AUTOSAR XML (schema 4-2-2)
package /STELLANTIS/EPT/SASWCs
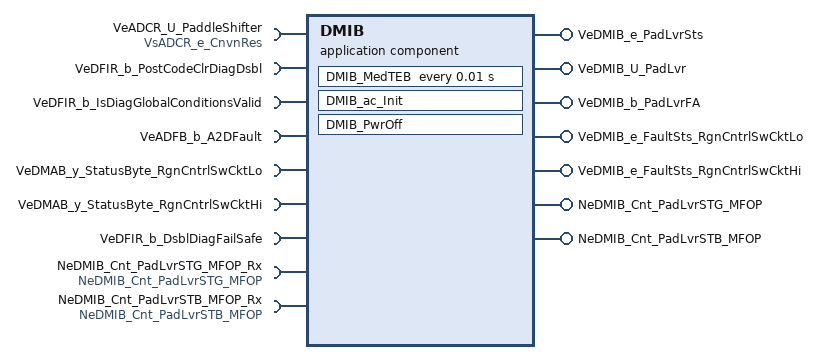
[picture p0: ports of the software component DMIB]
  application sw component type DMIB
    7 x require port:
      VeADCR_U_PaddleShifter: variation-point={short-label=vpVeADCR_U_PaddleShifter, sw-syscond=1}, nonqueued-receiver-com-spec{data-element=VsADCR_e_CnvnRes, init-value={short-label=DefaultInitValue_IDTRAdcInpResData, fields=[0, 0]}}, required-interface=VsADCR_e_CnvnRes
      VeDFIR_b_PostCodeClrDiagDsbl: variation-point={short-label=vpVeDFIR_b_PostCodeClrDiagDsbl, sw-syscond=1}, nonqueued-receiver-com-spec{data-element=Value, init-value=0}, required-interface=VeDFIR_b_PostCodeClrDiagDsbl
      VeDFIR_b_IsDiagGlobalConditionsValid: variation-point={short-label=vpVeDFIR_b_IsDiagGlobalConditionsValid, sw-syscond=1}, nonqueued-receiver-com-spec{data-element=Value, init-value=0}, required-interface=VeDFIR_b_IsDiagGlobalConditionsValid
      VeADFB_b_A2DFault: variation-point={short-label=vpVeADFB_b_A2DFault, sw-syscond=1}, nonqueued-receiver-com-spec{data-element=Value, init-value=0}, required-interface=VeADFB_b_A2DFault
      VeDMAB_y_StatusByte_RgnCntrlSwCktLo: variation-point={short-label=vpVeDMAB_y_StatusByte_RgnCntrlSwCktLo, sw-syscond=1}, nonqueued-receiver-com-spec{data-element=Value, init-value=0}, required-interface=VeDMAB_y_StatusByte_RgnCntrlSwCktLo
      VeDMAB_y_StatusByte_RgnCntrlSwCktHi: variation-point={short-label=vpVeDMAB_y_StatusByte_RgnCntrlSwCktHi, sw-syscond=1}, nonqueued-receiver-com-spec{data-element=Value, init-value=0}, required-interface=VeDMAB_y_StatusByte_RgnCntrlSwCktHi
      VeDFIR_b_DsblDiagFailSafe: variation-point={short-label=vpVeDFIR_b_DsblDiagFailSafe, sw-syscond=1}, nonqueued-receiver-com-spec{data-element=Value, init-value=0}, required-interface=VeDFIR_b_DsblDiagFailSafe
    5 x provide port:
      VeDMIB_e_PadLvrSts: variation-point={short-label=vpVeDMIB_e_PadLvrSts, sw-syscond=1}, nonqueued-sender-com-spec{data-element=Value, init-value=CeDMIR_e_Init}, provided-interface=VeDMIB_e_PadLvrSts
      VeDMIB_U_PadLvr: variation-point={short-label=vpVeDMIB_U_PadLvr, sw-syscond=1}, nonqueued-sender-com-spec{data-element=Value, init-value=0}, provided-interface=VeDMIB_U_PadLvr
      VeDMIB_b_PadLvrFA: variation-point={short-label=vpVeDMIB_b_PadLvrFA, sw-syscond=1}, nonqueued-sender-com-spec{data-element=Value, init-value=0}, provided-interface=VeDMIB_b_PadLvrFA
      VeDMIB_e_FaultSts_RgnCntrlSwCktLo: variation-point={short-label=vpVeDMIB_e_FaultSts_RgnCntrlSwCktLo, sw-syscond=1}, nonqueued-sender-com-spec{data-element=Value, init-value=CeDFIB_e_Init}, provided-interface=VeDMIB_e_FaultSts_RgnCntrlSwCktLo
      VeDMIB_e_FaultSts_RgnCntrlSwCktHi: variation-point={short-label=vpVeDMIB_e_FaultSts_RgnCntrlSwCktHi, sw-syscond=1}, nonqueued-sender-com-spec{data-element=Value, init-value=CeDFIB_e_Init}, provided-interface=VeDMIB_e_FaultSts_RgnCntrlSwCktHi
    require port NeDMIB_Cnt_PadLvrSTG_MFOP_Rx: variation-point={short-label=vpNeDMIB_Cnt_PadLvrSTG_MFOP_Rx, sw-syscond=1}, nv-require-com-spec{init-value=0, variable=NeDMIB_Cnt_PadLvrSTG_MFOP}, required-interface=NeDMIB_Cnt_PadLvrSTG_MFOP
    require port NeDMIB_Cnt_PadLvrSTB_MFOP_Rx: variation-point={short-label=vpNeDMIB_Cnt_PadLvrSTB_MFOP_Rx, sw-syscond=1}, nv-require-com-spec{init-value=0, variable=NeDMIB_Cnt_PadLvrSTB_MFOP}, required-interface=NeDMIB_Cnt_PadLvrSTB_MFOP
    provide port NeDMIB_Cnt_PadLvrSTG_MFOP: nv-provide-com-spec{ram-block-init-value=0, variable=NeDMIB_Cnt_PadLvrSTG_MFOP}, provided-interface=NeDMIB_Cnt_PadLvrSTG_MFOP
    provide port NeDMIB_Cnt_PadLvrSTB_MFOP: nv-provide-com-spec{ram-block-init-value=0, variable=NeDMIB_Cnt_PadLvrSTB_MFOP}, provided-interface=NeDMIB_Cnt_PadLvrSTB_MFOP
    behavior IB_DMIB: data-type-mapping=[msADTtoIDTMapping, ADTtoIDTMapping], handle-termination-and-restart=NO-SUPPORT
      timing event Event_MedTEB: start-on-event=DMIB_MedTEB, period=0.01
      init event Event_DMIB_ac_Init: start-on-event=DMIB_ac_Init
      init event Event_PwrOff: start-on-event=DMIB_PwrOff
      runnable DMIB_ac_Init
        data-receive-point-by-arguments:
          access IN_NeDMIB_Cnt_PadLvrSTB_MFOP_Rx_NeDMIB_Cnt_PadLvrSTB_MFOP: accessed-variable=NeDMIB_Cnt_PadLvrSTB_MFOP_Rx.NeDMIB_Cnt_PadLvrSTB_MFOP, variation-point={short-label=vpIN_NeDMIB_Cnt_PadLvrSTB_MFOP_Rx_NeDMIB_Cnt_PadLvrSTB_MFOP, sw-syscond=1}
          access IN_NeDMIB_Cnt_PadLvrSTG_MFOP_Rx_NeDMIB_Cnt_PadLvrSTG_MFOP: accessed-variable=NeDMIB_Cnt_PadLvrSTG_MFOP_Rx.NeDMIB_Cnt_PadLvrSTG_MFOP, variation-point={short-label=vpIN_NeDMIB_Cnt_PadLvrSTG_MFOP_Rx_NeDMIB_Cnt_PadLvrSTG_MFOP, sw-syscond=1}
        data-send-points:
          4 x access:
            OUT_VeDMIB_e_PadLvrSts_Value: accessed-variable=VeDMIB_e_PadLvrSts.Value, variation-point={short-label=vpOUT_VeDMIB_e_PadLvrSts_Value, sw-syscond=1}
            OUT_VeDMIB_U_PadLvr_Value: accessed-variable=VeDMIB_U_PadLvr.Value, variation-point={short-label=vpOUT_VeDMIB_U_PadLvr_Value, sw-syscond=1}
            OUT_VeDMIB_e_FaultSts_RgnCntrlSwCktLo_Value: accessed-variable=VeDMIB_e_FaultSts_RgnCntrlSwCktLo.Value, variation-point={short-label=vpOUT_VeDMIB_e_FaultSts_RgnCntrlSwCktLo_Value, sw-syscond=1}
            OUT_VeDMIB_e_FaultSts_RgnCntrlSwCktHi_Value: accessed-variable=VeDMIB_e_FaultSts_RgnCntrlSwCktHi.Value, variation-point={short-label=vpOUT_VeDMIB_e_FaultSts_RgnCntrlSwCktHi_Value, sw-syscond=1}
      runnable DMIB_MedTEB
        data-receive-point-by-arguments:
          7 x access:
            IN_VeADCR_U_PaddleShifter_VsADCR_e_CnvnRes: accessed-variable=VeADCR_U_PaddleShifter.VsADCR_e_CnvnRes, variation-point={short-label=vpIN_VeADCR_U_PaddleShifter_VsADCR_e_CnvnRes, sw-syscond=1}
            IN_VeADFB_b_A2DFault_Value: accessed-variable=VeADFB_b_A2DFault.Value, variation-point={short-label=vpIN_VeADFB_b_A2DFault_Value, sw-syscond=1}
            IN_VeDFIR_b_DsblDiagFailSafe_Value: accessed-variable=VeDFIR_b_DsblDiagFailSafe.Value, variation-point={short-label=vpIN_VeDFIR_b_DsblDiagFailSafe_Value, sw-syscond=1}
            IN_VeDFIR_b_IsDiagGlobalConditionsValid_Value: accessed-variable=VeDFIR_b_IsDiagGlobalConditionsValid.Value, variation-point={short-label=vpIN_VeDFIR_b_IsDiagGlobalConditionsValid_Value, sw-syscond=1}
            IN_VeDFIR_b_PostCodeClrDiagDsbl_Value: accessed-variable=VeDFIR_b_PostCodeClrDiagDsbl.Value, variation-point={short-label=vpIN_VeDFIR_b_PostCodeClrDiagDsbl_Value, sw-syscond=1}
            IN_VeDMAB_y_StatusByte_RgnCntrlSwCktHi_Value: accessed-variable=VeDMAB_y_StatusByte_RgnCntrlSwCktHi.Value, variation-point={short-label=vpIN_VeDMAB_y_StatusByte_RgnCntrlSwCktHi_Value, sw-syscond=1}
            IN_VeDMAB_y_StatusByte_RgnCntrlSwCktLo_Value: accessed-variable=VeDMAB_y_StatusByte_RgnCntrlSwCktLo.Value, variation-point={short-label=vpIN_VeDMAB_y_StatusByte_RgnCntrlSwCktLo_Value, sw-syscond=1}
        data-send-points:
          5 x access:
            OUT_VeDMIB_e_PadLvrSts_Value: accessed-variable=VeDMIB_e_PadLvrSts.Value, variation-point={short-label=vpOUT_VeDMIB_e_PadLvrSts_Value, sw-syscond=1}
            OUT_VeDMIB_U_PadLvr_Value: accessed-variable=VeDMIB_U_PadLvr.Value, variation-point={short-label=vpOUT_VeDMIB_U_PadLvr_Value, sw-syscond=1}
            OUT_VeDMIB_b_PadLvrFA_Value: accessed-variable=VeDMIB_b_PadLvrFA.Value, variation-point={short-label=vpOUT_VeDMIB_b_PadLvrFA_Value, sw-syscond=1}
            OUT_VeDMIB_e_FaultSts_RgnCntrlSwCktLo_Value: accessed-variable=VeDMIB_e_FaultSts_RgnCntrlSwCktLo.Value, variation-point={short-label=vpOUT_VeDMIB_e_FaultSts_RgnCntrlSwCktLo_Value, sw-syscond=1}
            OUT_VeDMIB_e_FaultSts_RgnCntrlSwCktHi_Value: accessed-variable=VeDMIB_e_FaultSts_RgnCntrlSwCktHi.Value, variation-point={short-label=vpOUT_VeDMIB_e_FaultSts_RgnCntrlSwCktHi_Value, sw-syscond=1}
      runnable DMIB_PwrOff
        data-send-points:
          access OUT_NeDMIB_Cnt_PadLvrSTG_MFOP_NeDMIB_Cnt_PadLvrSTG_MFOP: accessed-variable=NeDMIB_Cnt_PadLvrSTG_MFOP.NeDMIB_Cnt_PadLvrSTG_MFOP
          access OUT_NeDMIB_Cnt_PadLvrSTB_MFOP_NeDMIB_Cnt_PadLvrSTB_MFOP: accessed-variable=NeDMIB_Cnt_PadLvrSTB_MFOP.NeDMIB_Cnt_PadLvrSTB_MFOP
      variation point proxy Variant_DMIB_PaddleShifter_Presence: category=CONDITION, condition-access=1
